AUTOSAR XML (schema 4-2-1)
package /ComponentTypes
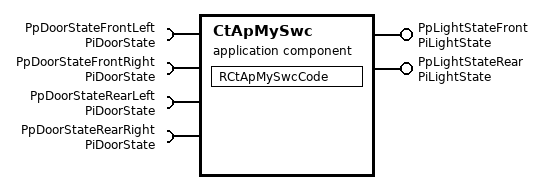
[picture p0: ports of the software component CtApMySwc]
  application sw component type CtApMySwc
    provide port PpLightStateFront: nonqueued-sender-com-spec{data-element=DeLightState, init-value=constant-reference=CLightOff}, provided-interface=PiLightState
    provide port PpLightStateRear: nonqueued-sender-com-spec{data-element=DeLightState, init-value=constant-reference=CLightOff}, provided-interface=PiLightState
    4 x require port, all with nonqueued-receiver-com-spec{data-element=DeDoorState, filter=data-filter-type=ALWAYS, init-value=constant-reference=CDoorClosed}, required-interface=PiDoorState:
      PpDoorStateFrontLeft
      PpDoorStateFrontRight
      PpDoorStateRearLeft
      PpDoorStateRearRight
    behavior CtApMySwc_InternalBehavior: data-type-mapping=DemoTypeMapping
      4 x data received event, all with start-on-event=RCtApMySwcCode:
        DRT_RCtApMySwcCode_PpDoorStateFrontLeft_DeDoorState: data=PpDoorStateFrontLeft.DeDoorState
        DRT_RCtApMySwcCode_PpDoorStateFrontRight_DeDoorState: data=PpDoorStateFrontRight.DeDoorState
        DRT_RCtApMySwcCode_PpDoorStateRearLeft_DeDoorState: data=PpDoorStateRearLeft.DeDoorState
        DRT_RCtApMySwcCode_PpDoorStateRearRight_DeDoorState: data=PpDoorStateRearRight.DeDoorState
      runnable RCtApMySwcCode
        data-read-access:
          access REC_PpDoorStateFrontLeft_Element: accessed-variable=PpDoorStateFrontLeft.DeDoorState
          access REC_PpDoorStateRearLeft_DeDoorState: accessed-variable=PpDoorStateRearLeft.DeDoorState
        data-receive-point-by-arguments:
          access REC_PpDoorStateFrontRight_Element: accessed-variable=PpDoorStateFrontRight.DeDoorState
          access REC_PpDoorStateRearRight_DeDoorState: accessed-variable=PpDoorStateRearRight.DeDoorState
        data-send-points:
          access SEND_PpLightStateFront_Element: accessed-variable=PpLightStateFront.DeLightState
          access SEND_PpLightStateRear_DeLightState: accessed-variable=PpLightStateRear.DeLightState
  swc implementation CtApMySwc_Implementation: behavior=CtApMySwc_InternalBehavior
    code-descriptors:
      code Default: artifact-descriptors=autosar-engineering-object={short-label=Default, category=SWSRC}
